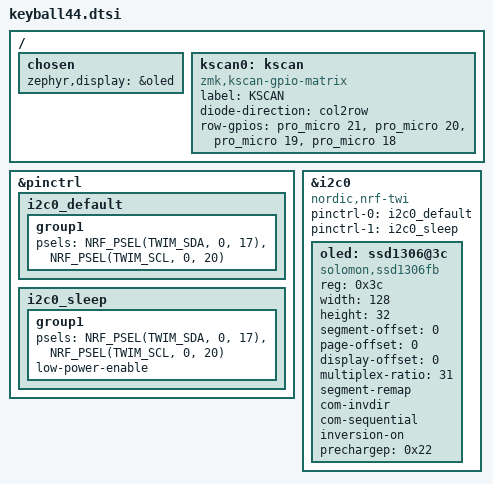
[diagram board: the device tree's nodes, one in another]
/*
 * Keyball44 keyboard-half base devicetree.
 *
 * The shared physical-layout + matrix-transform now live in keyball44_common.dtsi
 * (shared with the dongle). This file adds the parts that only a *keyboard half*
 * has: the real GPIO key matrix (kscan0) and the SSD1306/i2c OLED display.
 * The col-gpios are filled in per side in keyball44_{left,right}.overlay.
 */

#include "keyball44_common.dtsi"

/ {
    chosen {
        zephyr,display = &oled;
    };

    kscan0: kscan {
        compatible = "zmk,kscan-gpio-matrix";
        label = "KSCAN";

        diode-direction = "col2row";
		row-gpios
			= <&pro_micro 21 (GPIO_ACTIVE_HIGH | GPIO_PULL_DOWN)>
			, <&pro_micro 20 (GPIO_ACTIVE_HIGH | GPIO_PULL_DOWN)>
			, <&pro_micro 19 (GPIO_ACTIVE_HIGH | GPIO_PULL_DOWN)>
			, <&pro_micro 18 (GPIO_ACTIVE_HIGH | GPIO_PULL_DOWN)>
            ;
    };
};

&pinctrl {
    i2c0_default: i2c0_default {
        group1 {
            psels = <NRF_PSEL(TWIM_SDA, 0, 17)>,
                    <NRF_PSEL(TWIM_SCL, 0, 20)>;
        };
    };

    i2c0_sleep: i2c0_sleep {
        group1 {
            psels = <NRF_PSEL(TWIM_SDA, 0, 17)>,
                    <NRF_PSEL(TWIM_SCL, 0, 20)>;
            low-power-enable;
        };
    };
};

&i2c0 {
    status = "okay";
    compatible = "nordic,nrf-twi";
    pinctrl-0 = <&i2c0_default>;
    pinctrl-1 = <&i2c0_sleep>;
    pinctrl-names = "default", "sleep";

    oled: ssd1306@3c {
        compatible = "solomon,ssd1306fb";
        reg = <0x3c>;
        width = <128>;
        height = <32>;
        segment-offset = <0>;
        page-offset = <0>;
        display-offset = <0>;
        multiplex-ratio = <31>;
        segment-remap;
        com-invdir;
        com-sequential;
        inversion-on;
        prechargep = <0x22>;
    };
};
